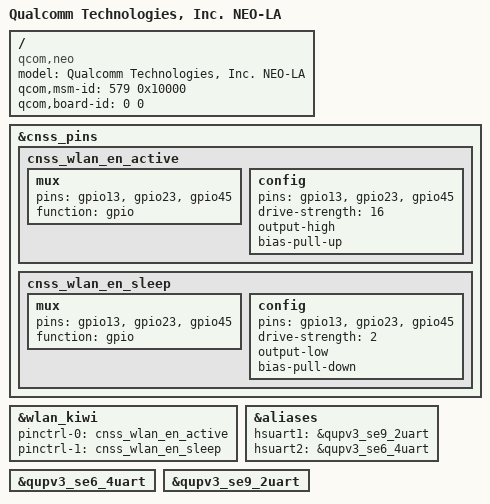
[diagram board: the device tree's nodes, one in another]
// SPDX-License-Identifier: GPL-2.0

/dts-v1/;

#include "vendor-base/qcom/neo_luna-v2.dtsi"
#include "vendor-base/qcom/neo_luna-v2-sg-idp.dtsi"
#include "meta-neo-base.dtsi"

/ {
	model = "Qualcomm Technologies, Inc. NEO-LA";
	compatible = "qcom,neo";
	qcom,msm-id = <579 0x10000>;
	qcom,board-id = <0 0>;
};

/* Enable/disable buck converter for wifi card */

&cnss_pins {
	cnss_wlan_en_active: cnss_wlan_en_active {
		mux {
			pins = "gpio13", "gpio23", "gpio45";
			function = "gpio";
		};

		config {
			pins = "gpio13", "gpio23", "gpio45";
			drive-strength = <16>;
			output-high;
			bias-pull-up;
		};
	};

	cnss_wlan_en_sleep: cnss_wlan_en_sleep {
		mux {
			pins = "gpio13", "gpio23", "gpio45";
			function = "gpio";
		};

		config {
			pins = "gpio13", "gpio23", "gpio45";
			drive-strength = <2>;
			output-low;
			bias-pull-down;
		};
	};
};

&wlan_kiwi {
	pinctrl-0 = <&cnss_wlan_en_active>;
	pinctrl-1 = <&cnss_wlan_en_sleep>;
};

/* Acropolis UART0 port */
&aliases {
	hsuart1 = &qupv3_se9_2uart;
	hsuart2 = &qupv3_se6_4uart;
};

&qupv3_se6_4uart {
	status = "ok";
};

&qupv3_se9_2uart {
	status = "ok";
};
